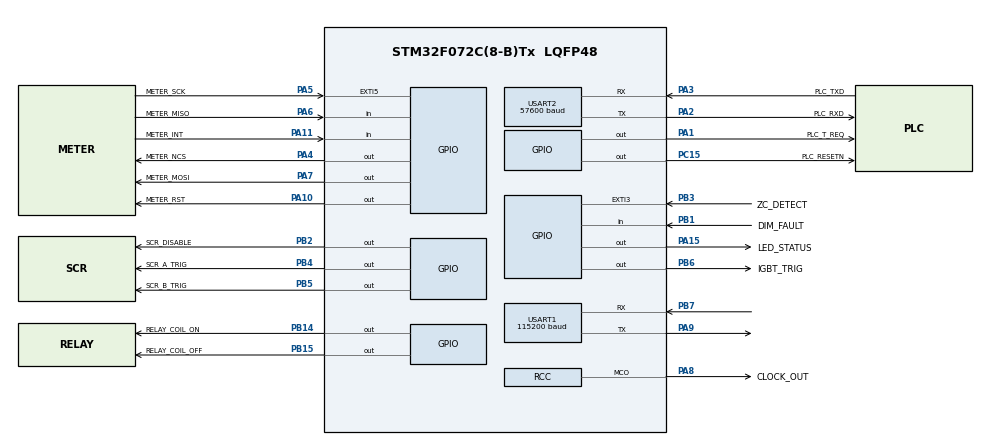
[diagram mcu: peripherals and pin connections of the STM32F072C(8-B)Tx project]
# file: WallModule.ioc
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Mcu.Family=STM32F0
Mcu.Name=STM32F072C(8-B)Tx
Mcu.Package=LQFP48
NVIC.EXTI2_3_IRQn=true\:0\:0\:false\:false\:true\:true\:true\:true
NVIC.TIM1_BRK_UP_TRG_COM_IRQn=true\:0\:0\:false\:false\:true\:true\:true\:true
NVIC.TIM2_IRQn=true\:0\:0\:false\:false\:true\:true\:true\:true
NVIC.USART1_IRQn=true\:0\:0\:false\:false\:true\:true\:true\:true
NVIC.USART2_IRQn=true\:0\:0\:false\:false\:true\:true\:true\:true
PA1.GPIO_Label=PLC_T_REQ
PA1.GPIO_Speed=GPIO_SPEED_FREQ_HIGH
PA1.Signal=GPIO_Output
PA10.GPIO_Label=METER_RST
PA10.Signal=GPIO_Output
PA11.GPIO_Label=METER_INT
PA11.Signal=GPIO_Input
PA13.Mode=Serial_Wire
PA13.Signal=SYS_SWDIO
PA14.Mode=Serial_Wire
PA14.Signal=SYS_SWCLK
PA15.GPIO_Label=LED_STATUS
PA15.Signal=GPIO_Output
PA2.GPIO_Label=PLC_RXD
PA2.Mode=Asynchronous
PA2.Signal=USART2_TX
PA3.GPIO_Label=PLC_TXD
PA3.Mode=Asynchronous
PA3.Signal=USART2_RX
PA4.GPIO_Label=METER_NCS
PA4.Signal=GPIO_Output
PA5.GPIO_Label=METER_SCK
PA5.Signal=GPXTI5
PA6.GPIO_Label=METER_MISO
PA6.Signal=GPIO_Input
PA7.GPIO_Label=METER_MOSI
PA7.Signal=GPIO_Output
PA8.GPIO_Label=CLOCK_OUT
PA8.Mode=Clock-out
PA8.Signal=RCC_MCO
PA9.Mode=Asynchronous
PA9.Signal=USART1_TX
PB1.GPIO_Label=DIM_FAULT
PB1.GPIO_PuPd=GPIO_PULLUP
PB1.Signal=GPIO_Input
PB14.GPIO_Label=RELAY_COIL_ON
PB14.Signal=GPIO_Output
PB15.GPIO_Label=RELAY_COIL_OFF
PB15.Signal=GPIO_Output
PB2.GPIO_Label=SCR_DISABLE
PB2.Signal=GPIO_Output
PB3.GPIO_Label=ZC_DETECT
PB3.Signal=GPXTI3
PB4.GPIO_Label=SCR_A_TRIG
PB4.Signal=GPIO_Output
PB5.GPIO_Label=SCR_B_TRIG
PB5.Signal=GPIO_Output
PB6.GPIO_Label=IGBT_TRIG
PB6.Signal=GPIO_Output
PB7.Mode=Asynchronous
PB7.Signal=USART1_RX
PC15-OSC32_OUT.GPIO_Label=PLC_RESETN
PC15-OSC32_OUT.GPIO_Speed=GPIO_SPEED_FREQ_LOW
PC15-OSC32_OUT.Signal=GPIO_Output
ProjectManager.HeapSize=0x200
ProjectManager.StackSize=0x400
ProjectManager.TargetToolchain=STM32CubeIDE
RCC.AHBCLKDivider=RCC_SYSCLK_DIV2
RCC.AHBFreq_Value=4000000
RCC.APB1Freq_Value=4000000
RCC.APB1TimFreq_Value=4000000
RCC.HCLKFreq_Value=4000000
TIM1.CounterMode=TIM_COUNTERMODE_UP
TIM1.Period=60000
TIM1.Prescaler=15
TIM2.Period=124
TIM2.Prescaler=15
USART1.BaudRate=115200
USART1.VirtualMode-Asynchronous=VM_ASYNC
USART2.BaudRate=57600
USART2.VirtualMode-Asynchronous=VM_ASYNC
VP_TIM1_VS_ClockSourceINT.Mode=Internal
VP_TIM2_VS_ClockSourceINT.Mode=Internal
board=custom

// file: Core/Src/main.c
/* USER CODE BEGIN Header */
/**
  ******************************************************************************
  * @file           : main.c
  * @brief          : Main program body
  ******************************************************************************
  * @attention
  *
  * Copyright (c) 2024 STMicroelectronics.
  * All rights reserved.
  *
  * This software is licensed under terms that can be found in the LICENSE file
  * in the root directory of this software component.
  * If no LICENSE file comes with this software, it is provided AS-IS.
  *
  ******************************************************************************
  */
/* USER CODE END Header */
#include "main.h"
#include "dimmer.h"

TIM_HandleTypeDef htim1;
TIM_HandleTypeDef htim2;

UART_HandleTypeDef huart1;
UART_HandleTypeDef huart2;

void SystemClock_Config(void);
static void MX_GPIO_Init(void);
static void MX_USART1_UART_Init(void);
static void MX_USART2_UART_Init(void);
static void MX_TIM1_Init(void);
static void MX_TIM2_Init(void);

int main(void)
{

  /* MCU Configuration--------------------------------------------------------*/

  /* Reset of all peripherals, Initializes the Flash interface and the Systick. */
  HAL_Init();

  /* Configure the system clock */
  SystemClock_Config();

  /* Initialize all configured peripherals */
  MX_GPIO_Init();
  MX_USART1_UART_Init();
  MX_USART2_UART_Init();
  MX_TIM1_Init();
  MX_TIM2_Init();
  /* USER CODE BEGIN 2 */

  DIM_Init();

  /* USER CODE END 2 */

  /* Infinite loop */
  while (1)
  {

    /* USER CODE BEGIN 3 */
	DIM_Process();

  }
  /* USER CODE END 3 */
}

void SystemClock_Config(void)
{
  RCC_OscInitTypeDef RCC_OscInitStruct = {0};
  RCC_ClkInitTypeDef RCC_ClkInitStruct = {0};
  RCC_PeriphCLKInitTypeDef PeriphClkInit = {0};

  /** Initializes the RCC Oscillators according to the specified parameters
  * in the RCC_OscInitTypeDef structure.
  */
  RCC_OscInitStruct.OscillatorType = RCC_OSCILLATORTYPE_HSI;
  RCC_OscInitStruct.HSIState = RCC_HSI_ON;
  RCC_OscInitStruct.HSICalibrationValue = RCC_HSICALIBRATION_DEFAULT;
  RCC_OscInitStruct.PLL.PLLState = RCC_PLL_NONE;
  if (HAL_RCC_OscConfig(&RCC_OscInitStruct) != HAL_OK)
  {
    Error_Handler();
  }

  /** Initializes the CPU, AHB and APB buses clocks
  */
  RCC_ClkInitStruct.ClockType = RCC_CLOCKTYPE_HCLK|RCC_CLOCKTYPE_SYSCLK
                              |RCC_CLOCKTYPE_PCLK1;
  RCC_ClkInitStruct.SYSCLKSource = RCC_SYSCLKSOURCE_HSI;
  RCC_ClkInitStruct.AHBCLKDivider = RCC_SYSCLK_DIV2;
  RCC_ClkInitStruct.APB1CLKDivider = RCC_HCLK_DIV1;

  if (HAL_RCC_ClockConfig(&RCC_ClkInitStruct, FLASH_LATENCY_0) != HAL_OK)
  {
    Error_Handler();
  }
  PeriphClkInit.PeriphClockSelection = RCC_PERIPHCLK_USART1|RCC_PERIPHCLK_USART2;
  PeriphClkInit.Usart1ClockSelection = RCC_USART1CLKSOURCE_PCLK1;
  PeriphClkInit.Usart2ClockSelection = RCC_USART2CLKSOURCE_PCLK1;
  if (HAL_RCCEx_PeriphCLKConfig(&PeriphClkInit) != HAL_OK)
  {
    Error_Handler();
  }
  HAL_RCC_MCOConfig(RCC_MCO, RCC_MCO1SOURCE_SYSCLK, RCC_MCODIV_1);
}

static void MX_TIM1_Init(void)
{

  TIM_ClockConfigTypeDef sClockSourceConfig = {0};
  TIM_MasterConfigTypeDef sMasterConfig = {0};

  htim1.Instance = TIM1;
  htim1.Init.Prescaler = 15;
  htim1.Init.CounterMode = TIM_COUNTERMODE_UP;
  htim1.Init.Period = 60000;
  htim1.Init.ClockDivision = TIM_CLOCKDIVISION_DIV1;
  htim1.Init.RepetitionCounter = 0;
  htim1.Init.AutoReloadPreload = TIM_AUTORELOAD_PRELOAD_DISABLE;
  if (HAL_TIM_Base_Init(&htim1) != HAL_OK)
  {
    Error_Handler();
  }
  sClockSourceConfig.ClockSource = TIM_CLOCKSOURCE_INTERNAL;
  if (HAL_TIM_ConfigClockSource(&htim1, &sClockSourceConfig) != HAL_OK)
  {
    Error_Handler();
  }
  sMasterConfig.MasterOutputTrigger = TIM_TRGO_RESET;
  sMasterConfig.MasterSlaveMode = TIM_MASTERSLAVEMODE_DISABLE;
  if (HAL_TIMEx_MasterConfigSynchronization(&htim1, &sMasterConfig) != HAL_OK)
  {
    Error_Handler();
  }

}

static void MX_TIM2_Init(void)
{

  TIM_ClockConfigTypeDef sClockSourceConfig = {0};
  TIM_MasterConfigTypeDef sMasterConfig = {0};

  htim2.Instance = TIM2;
  htim2.Init.Prescaler = 15;
  htim2.Init.CounterMode = TIM_COUNTERMODE_UP;
  htim2.Init.Period = 124;
  htim2.Init.ClockDivision = TIM_CLOCKDIVISION_DIV1;
  htim2.Init.AutoReloadPreload = TIM_AUTORELOAD_PRELOAD_DISABLE;
  if (HAL_TIM_Base_Init(&htim2) != HAL_OK)
  {
    Error_Handler();
  }
  sClockSourceConfig.ClockSource = TIM_CLOCKSOURCE_INTERNAL;
  if (HAL_TIM_ConfigClockSource(&htim2, &sClockSourceConfig) != HAL_OK)
  {
    Error_Handler();
  }
  sMasterConfig.MasterOutputTrigger = TIM_TRGO_RESET;
  sMasterConfig.MasterSlaveMode = TIM_MASTERSLAVEMODE_DISABLE;
  if (HAL_TIMEx_MasterConfigSynchronization(&htim2, &sMasterConfig) != HAL_OK)
  {
    Error_Handler();
  }

}

static void MX_USART1_UART_Init(void)
{

  huart1.Instance = USART1;
  huart1.Init.BaudRate = 115200;
  huart1.Init.WordLength = UART_WORDLENGTH_8B;
  huart1.Init.StopBits = UART_STOPBITS_1;
  huart1.Init.Parity = UART_PARITY_NONE;
  huart1.Init.Mode = UART_MODE_TX_RX;
  huart1.Init.HwFlowCtl = UART_HWCONTROL_NONE;
  huart1.Init.OverSampling = UART_OVERSAMPLING_16;
  huart1.Init.OneBitSampling = UART_ONE_BIT_SAMPLE_DISABLE;
  huart1.AdvancedInit.AdvFeatureInit = UART_ADVFEATURE_NO_INIT;
  if (HAL_UART_Init(&huart1) != HAL_OK)
  {
    Error_Handler();
  }

}

static void MX_USART2_UART_Init(void)
{

  huart2.Instance = USART2;
  huart2.Init.BaudRate = 57600;
  huart2.Init.WordLength = UART_WORDLENGTH_8B;
  huart2.Init.StopBits = UART_STOPBITS_1;
  huart2.Init.Parity = UART_PARITY_NONE;
  huart2.Init.Mode = UART_MODE_TX_RX;
  huart2.Init.HwFlowCtl = UART_HWCONTROL_NONE;
  huart2.Init.OverSampling = UART_OVERSAMPLING_16;
  huart2.Init.OneBitSampling = UART_ONE_BIT_SAMPLE_DISABLE;
  huart2.AdvancedInit.AdvFeatureInit = UART_ADVFEATURE_NO_INIT;
  if (HAL_UART_Init(&huart2) != HAL_OK)
  {
    Error_Handler();
  }

}

static void MX_GPIO_Init(void)
{
  GPIO_InitTypeDef GPIO_InitStruct = {0};

  /* GPIO Ports Clock Enable */
  __HAL_RCC_GPIOC_CLK_ENABLE();
  __HAL_RCC_GPIOA_CLK_ENABLE();
  __HAL_RCC_GPIOB_CLK_ENABLE();

  /*Configure GPIO pin Output Level */
  HAL_GPIO_WritePin(PLC_RESETN_GPIO_Port, PLC_RESETN_Pin, GPIO_PIN_RESET);

  /*Configure GPIO pin Output Level */
  HAL_GPIO_WritePin(GPIOA, PLC_T_REQ_Pin|METER_NCS_Pin|METER_MOSI_Pin|METER_RST_Pin
                          |LED_STATUS_Pin, GPIO_PIN_RESET);

  /*Configure GPIO pin Output Level */
  HAL_GPIO_WritePin(GPIOB, SCR_DISABLE_Pin|RELAY_COIL_ON_Pin|RELAY_COIL_OFF_Pin|SCR_A_TRIG_Pin
                          |SCR_B_TRIG_Pin|IGBT_TRIG_Pin, GPIO_PIN_RESET);

  /*Configure GPIO pin : PLC_RESETN_Pin */
  GPIO_InitStruct.Pin = PLC_RESETN_Pin;
  GPIO_InitStruct.Mode = GPIO_MODE_OUTPUT_PP;
  GPIO_InitStruct.Pull = GPIO_NOPULL;
  GPIO_InitStruct.Speed = GPIO_SPEED_FREQ_LOW;
  HAL_GPIO_Init(PLC_RESETN_GPIO_Port, &GPIO_InitStruct);

  /*Configure GPIO pin : PLC_T_REQ_Pin */
  GPIO_InitStruct.Pin = PLC_T_REQ_Pin;
  GPIO_InitStruct.Mode = GPIO_MODE_OUTPUT_PP;
  GPIO_InitStruct.Pull = GPIO_NOPULL;
  GPIO_InitStruct.Speed = GPIO_SPEED_FREQ_HIGH;
  HAL_GPIO_Init(PLC_T_REQ_GPIO_Port, &GPIO_InitStruct);

  /*Configure GPIO pins : METER_NCS_Pin METER_MOSI_Pin METER_RST_Pin LED_STATUS_Pin */
  GPIO_InitStruct.Pin = METER_NCS_Pin|METER_MOSI_Pin|METER_RST_Pin|LED_STATUS_Pin;
  GPIO_InitStruct.Mode = GPIO_MODE_OUTPUT_PP;
  GPIO_InitStruct.Pull = GPIO_NOPULL;
  GPIO_InitStruct.Speed = GPIO_SPEED_FREQ_LOW;
  HAL_GPIO_Init(GPIOA, &GPIO_InitStruct);

  /*Configure GPIO pin : METER_SCK_Pin */
  GPIO_InitStruct.Pin = METER_SCK_Pin;
  GPIO_InitStruct.Mode = GPIO_MODE_IT_RISING;
  GPIO_InitStruct.Pull = GPIO_NOPULL;
  HAL_GPIO_Init(METER_SCK_GPIO_Port, &GPIO_InitStruct);

  /*Configure GPIO pins : METER_MISO_Pin METER_INT_Pin */
  GPIO_InitStruct.Pin = METER_MISO_Pin|METER_INT_Pin;
  GPIO_InitStruct.Mode = GPIO_MODE_INPUT;
  GPIO_InitStruct.Pull = GPIO_NOPULL;
  HAL_GPIO_Init(GPIOA, &GPIO_InitStruct);

  /*Configure GPIO pin : DIM_FAULT_Pin */
  GPIO_InitStruct.Pin = DIM_FAULT_Pin;
  GPIO_InitStruct.Mode = GPIO_MODE_INPUT;
  GPIO_InitStruct.Pull = GPIO_PULLUP;
  HAL_GPIO_Init(DIM_FAULT_GPIO_Port, &GPIO_InitStruct);

  /*Configure GPIO pins : SCR_DISABLE_Pin RELAY_COIL_ON_Pin RELAY_COIL_OFF_Pin SCR_A_TRIG_Pin
                           SCR_B_TRIG_Pin IGBT_TRIG_Pin */
  GPIO_InitStruct.Pin = SCR_DISABLE_Pin|RELAY_COIL_ON_Pin|RELAY_COIL_OFF_Pin|SCR_A_TRIG_Pin
                          |SCR_B_TRIG_Pin|IGBT_TRIG_Pin;
  GPIO_InitStruct.Mode = GPIO_MODE_OUTPUT_PP;
  GPIO_InitStruct.Pull = GPIO_NOPULL;
  GPIO_InitStruct.Speed = GPIO_SPEED_FREQ_LOW;
  HAL_GPIO_Init(GPIOB, &GPIO_InitStruct);

  /*Configure GPIO pin : CLOCK_OUT_Pin */
  GPIO_InitStruct.Pin = CLOCK_OUT_Pin;
  GPIO_InitStruct.Mode = GPIO_MODE_AF_PP;
  GPIO_InitStruct.Pull = GPIO_NOPULL;
  GPIO_InitStruct.Speed = GPIO_SPEED_FREQ_LOW;
  GPIO_InitStruct.Alternate = GPIO_AF0_MCO;
  HAL_GPIO_Init(CLOCK_OUT_GPIO_Port, &GPIO_InitStruct);

  /*Configure GPIO pin : ZC_DETECT_Pin */
  GPIO_InitStruct.Pin = ZC_DETECT_Pin;
  GPIO_InitStruct.Mode = GPIO_MODE_IT_RISING;
  GPIO_InitStruct.Pull = GPIO_NOPULL;
  HAL_GPIO_Init(ZC_DETECT_GPIO_Port, &GPIO_InitStruct);

  /* EXTI interrupt init*/
  HAL_NVIC_SetPriority(EXTI2_3_IRQn, 0, 0);
  HAL_NVIC_EnableIRQ(EXTI2_3_IRQn);

}

void Error_Handler(void)
{
  __disable_irq();
  while (1)
  {
  }
}
